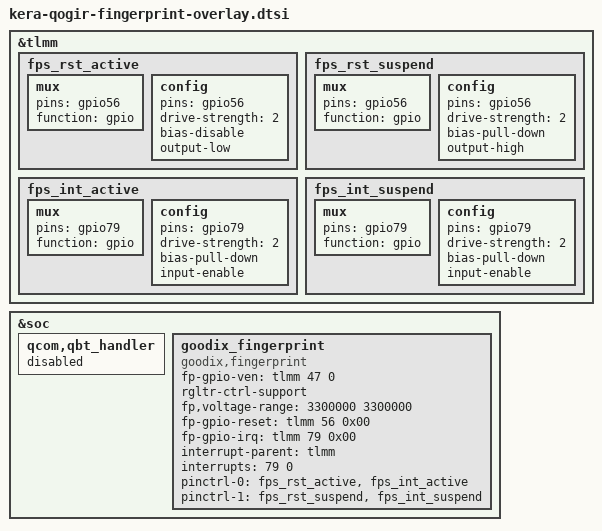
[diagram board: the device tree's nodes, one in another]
/*
 * Copyright (C) 2025 Motorola Mobility LLC.
 * All Rights Reserved.
 *
 * Motorola Mobility Confidential Restricted.
 *
 * Goodix GF3656 device tree config for SM7750 - Falcon
 *
 * author: chengql2@motorola.com
 * date: July 18, 2025
 */

#include <dt-bindings/regulator/qcom,rpmh-regulator-levels.h>

&tlmm {

	fps_rst_active: fps_rst_active {
			/* RESET */
			mux {
				pins = "gpio56";
				function = "gpio";
			};
			config {
				pins = "gpio56";
				drive-strength = <2>; /* 2 MA */
				bias-disable;
				output-low;
			};
	};

	fps_rst_suspend: fps_rst_suspend {
		/* sleep state */
		mux {
			pins = "gpio56";
			function = "gpio";
		};

		config {
			pins = "gpio56";
			drive-strength = <2>; /* 2 MA */
			bias-pull-down; /* pull down */
			output-high;
		};
	};

	fps_int_active: fps_int_active {
		/* active state */
		mux {
			pins = "gpio79";
			function = "gpio";
		};

		config {
			pins = "gpio79";
			drive-strength = <2>; /* 2 MA */
			bias-pull-down; /* pull down */
			input-enable;
		};
	};

	fps_int_suspend: fps_int_suspend {
		/* sleep state */
		mux {
			pins = "gpio79";
			function = "gpio";
		};

		config {
			pins = "gpio79";
			drive-strength = <2>; /* 2 MA */
			bias-pull-down; /* pull down */
			input-enable;
		};
	};
};

&soc {
	qcom,qbt_handler {
		status = "disabled";
	};
	goodix_fingerprint {
		compatible = "goodix,fingerprint";
		status = "ok";
		fp-gpio-ven = <&tlmm 47 0>;
		rgltr-ctrl-support;
		fp,voltage-range = <3300000 3300000>;
		fp-gpio-reset = <&tlmm 56 0x00>;
		fp-gpio-irq = <&tlmm 79 0x00>;
		interrupt-parent = <&tlmm>;
		interrupts = <79 0>;
		pinctrl-names = "default", "suspend";
		pinctrl-0 = <&fps_rst_active &fps_int_active>;
		pinctrl-1 = <&fps_rst_suspend &fps_int_suspend>;
	};
};
